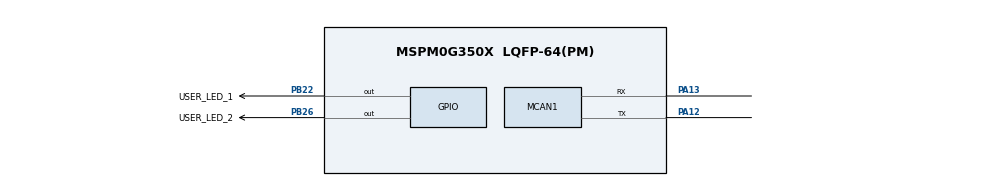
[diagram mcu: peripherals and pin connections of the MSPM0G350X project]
/**
 * @cliArgs --device "MSPM0G350X" --part "Default" --package "LQFP-64(PM)" --product "mspm0_sdk@2.02.00.05"
 * @versions {"tool":"1.21.0+3721"}
 */

/**
 * Import the modules used in this configuration.
 */
const GPIO   = scripting.addModule("/ti/driverlib/GPIO", {}, false);
const GPIO1  = GPIO.addInstance();
const GPIO2  = GPIO.addInstance();
const I2C    = scripting.addModule("/ti/driverlib/I2C", {}, false);
const I2C1   = I2C.addInstance();
const MCAN   = scripting.addModule("/ti/driverlib/MCAN", {}, false);
const MCAN1  = MCAN.addInstance();
const SYSCTL = scripting.addModule("/ti/driverlib/SYSCTL");

/**
 * Write custom configuration values to the imported modules.
 */
const mux4       = system.clockTree["EXHFMUX"];
mux4.inputSelect = "EXHFMUX_XTAL";

const pinFunction4        = system.clockTree["HFXT"];
pinFunction4.enable       = true;
pinFunction4.HFXTStartup  = 10;
pinFunction4.HFCLKMonitor = true;
pinFunction4.inputFreq    = 40;

GPIO1.$name                         = "GPIO_LEDS";
GPIO1.port                          = "PORTB";
GPIO1.associatedPins.create(3);
GPIO1.associatedPins[0].$name       = "USER_LED_1";
GPIO1.associatedPins[0].assignedPin = "22";
GPIO1.associatedPins[0].pin.$assign = "PB22";
GPIO1.associatedPins[1].$name       = "USER_LED_2";
GPIO1.associatedPins[1].assignedPin = "26";
GPIO1.associatedPins[1].pin.$assign = "PB26";
GPIO1.associatedPins[2].$name       = "PIN_2";

const Board = scripting.addModule("/ti/driverlib/Board", {}, false);

GPIO2.$name                              = "GPIO_SWITCHES";
GPIO2.port                               = "PORTB";
GPIO2.portSegment                        = "Upper";
GPIO2.associatedPins[0].$name            = "USER_SWITCH_1";
GPIO2.associatedPins[0].direction        = "INPUT";
GPIO2.associatedPins[0].internalResistor = "PULL_UP";
GPIO2.associatedPins[0].assignedPin      = "21";
GPIO2.associatedPins[0].interruptEn      = true;
GPIO2.associatedPins[0].polarity         = "FALL";

I2C1.$name                             = "I2C";
I2C1.basicEnableTarget                 = true;
I2C1.basicEnableController             = true;
I2C1.basicTargetAddress                = 0x48;
I2C1.basicControllerStandardBusSpeed   = "Fast";
I2C1.advAnalogGlitchFilter             = "DISABLED";
I2C1.advControllerTXFIFOTRIG           = "BYTES_1";
I2C1.advTargetTXFIFOTRIG               = "BYTES_1";
I2C1.advTargetTXEmptyEn                = true;
I2C1.intTarget                         = ["RXFIFO_TRIGGER","START","STOP","TX_DONE"];
I2C1.intController                     = ["ARBITRATION_LOST","NACK","RXFIFO_TRIGGER","RX_DONE","TX_DONE"];
I2C1.sdaPinConfig.$name                = "ti_driverlib_gpio_GPIOPinGeneric2";
I2C1.sdaPinConfig.hideOutputInversion  = scripting.forceWrite(false);
I2C1.sdaPinConfig.onlyInternalResistor = scripting.forceWrite(false);
I2C1.sdaPinConfig.passedPeripheralType = scripting.forceWrite("Digital");
I2C1.sclPinConfig.$name                = "ti_driverlib_gpio_GPIOPinGeneric3";
I2C1.sclPinConfig.hideOutputInversion  = scripting.forceWrite(false);
I2C1.sclPinConfig.onlyInternalResistor = scripting.forceWrite(false);
I2C1.sclPinConfig.passedPeripheralType = scripting.forceWrite("Digital");

MCAN1.$name                    = "MCAN0";
MCAN1.wkupReqEnable            = true;
MCAN1.autoWkupEnable           = true;
MCAN1.emulationEnable          = true;
MCAN1.tdcEnable                = true;
MCAN1.additionalCoreConfig     = true;
MCAN1.rrfe                     = true;
MCAN1.rrfs                     = true;
MCAN1.anfe                     = "1";
MCAN1.anfs                     = "1";
MCAN1.txEventFIFOWaterMark     = 0;
MCAN1.rxFIFO0waterMark         = 0;
MCAN1.enableInterrupt          = true;
MCAN1.interruptLine            = ["DL_MCAN_INTR_LINE_NUM_1"];
MCAN1.interruptLine1Flag       = ["DL_MCAN_INTR_MASK_ALL"];
MCAN1.m0interrupts             = ["DL_MCAN_MSP_INTERRUPT_LINE1"];
MCAN1.overrideRetention        = true;
MCAN1.desiredNomRate           = 250;
MCAN1.stdFiltType              = "01";
MCAN1.stdFiltElem              = "001";
MCAN1.flesa                    = 0;
MCAN1.lse                      = 0;
MCAN1.desiredDataRate          = 2;
MCAN1.interruptFlags           = ["DL_MCAN_INTERRUPT_ARA","DL_MCAN_INTERRUPT_BEU","DL_MCAN_INTERRUPT_BO","DL_MCAN_INTERRUPT_DRX","DL_MCAN_INTERRUPT_ELO","DL_MCAN_INTERRUPT_EP","DL_MCAN_INTERRUPT_EW","DL_MCAN_INTERRUPT_MRAF","DL_MCAN_INTERRUPT_PEA","DL_MCAN_INTERRUPT_PED","DL_MCAN_INTERRUPT_RF0N","DL_MCAN_INTERRUPT_TC","DL_MCAN_INTERRUPT_TEFN","DL_MCAN_INTERRUPT_TOO","DL_MCAN_INTERRUPT_TSW","DL_MCAN_INTERRUPT_WDI"];
MCAN1.stdFiltID1               = 3;
MCAN1.stdFiltID2               = 4;
MCAN1.spPercent                = 80;
MCAN1.txStartAddr              = 12;
MCAN1.txFIFOSize               = 10;
MCAN1.txEventFIFOStartAddr     = 640;
MCAN1.peripheral.$assign       = "CANFD0";
MCAN1.peripheral.rxPin.$assign = "PA13";
MCAN1.peripheral.txPin.$assign = "PA12";
MCAN1.txPinConfig.$name        = "ti_driverlib_gpio_GPIOPinGeneric0";
MCAN1.rxPinConfig.$name        = "ti_driverlib_gpio_GPIOPinGeneric1";

SYSCTL.CANCLKSource          = "HFCLK";
SYSCTL.useHFCLK_Manual       = true;
SYSCTL.HFCLKSource           = "HFXT";
SYSCTL.HFCLK_Freq            = 48000000;
SYSCTL.HFCLKMonitor          = true;
SYSCTL.HFXTStartup           = 10;
SYSCTL.forceDefaultClkConfig = true;
SYSCTL.clockTreeEn           = true;

/**
 * Pinmux solution for unlocked pins/peripherals. This ensures that minor changes to the automatic solver in a future
 * version of the tool will not impact the pinmux you originally saw.  These lines can be completely deleted in order to
 * re-solve from scratch.
 */
pinFunction4.peripheral.$suggestSolution           = "SYSCTL";
pinFunction4.peripheral.hfxInPin.$suggestSolution  = "PA5";
pinFunction4.peripheral.hfxOutPin.$suggestSolution = "PA6";
GPIO1.associatedPins[2].pin.$suggestSolution       = "PB13";
Board.peripheral.$suggestSolution                  = "DEBUGSS";
Board.peripheral.swclkPin.$suggestSolution         = "PA20";
Board.peripheral.swdioPin.$suggestSolution         = "PA19";
GPIO2.associatedPins[0].pin.$suggestSolution       = "PB21";
I2C1.peripheral.$suggestSolution                   = "I2C0";
I2C1.peripheral.sdaPin.$suggestSolution            = "PA0";
I2C1.peripheral.sclPin.$suggestSolution            = "PA1";
